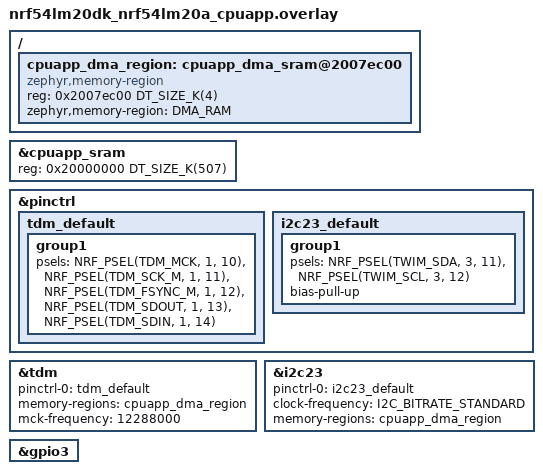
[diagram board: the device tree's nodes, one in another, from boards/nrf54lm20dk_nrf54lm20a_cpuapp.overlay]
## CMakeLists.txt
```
cmake_minimum_required(VERSION 3.20.0)
find_package(Zephyr REQUIRED HINTS $ENV{ZEPHYR_BASE})
project(flexlink_radio_test VERSION 0.1.0 LANGUAGES C)

set(TINYUSB_DIR ${CMAKE_CURRENT_SOURCE_DIR}/tinyusb)

if(DEFINED ZEPHYR_HAL_NORDIC_MODULE_DIR)
    set(HAL_NORDIC_DIR ${ZEPHYR_HAL_NORDIC_MODULE_DIR})
else()
    set(HAL_NORDIC_DIR ${ZEPHYR_BASE}/../modules/hal/nordic)
endif()

target_sources(app PRIVATE
    src/main.c
    src/app_control.c
    src/cli.c
    src/audio_io/audio_path_common.c
    src/audio_io/audio_path_wired.c
    src/audio_io/audio_path_wireless.c
    src/audio_io/i2s.c
    src/audio_io/i2s_tone.c
    src/audio_io/nau88l21.c
    src/prop_gfsk/radio_hw.c
    src/prop_gfsk/link.c
    src/prop_gfsk/test_mode.c
    src/usb/usb_device.c
    src/usb/usb_audio.c
    src/usb/usb_cdc.c
    src/usb/usb_descriptors.c
    ${TINYUSB_DIR}/src/tusb.c
    ${TINYUSB_DIR}/src/device/usbd.c
    ${TINYUSB_DIR}/src/device/usbd_control.c
    ${TINYUSB_DIR}/src/common/tusb_fifo.c
    ${TINYUSB_DIR}/src/class/cdc/cdc_device.c
    ${TINYUSB_DIR}/src/class/audio/audio_device.c
    ${TINYUSB_DIR}/src/portable/synopsys/dwc2/dcd_dwc2.c
    ${TINYUSB_DIR}/src/portable/synopsys/dwc2/dwc2_common.c
)

target_include_directories(app PRIVATE
    ${CMAKE_CURRENT_SOURCE_DIR}/src
    ${CMAKE_CURRENT_SOURCE_DIR}/src/usb
    ${ZEPHYR_BASE}/modules/hal_nordic/nrfx
    ${TINYUSB_DIR}/src
    ${TINYUSB_DIR}/hw
    ${TINYUSB_DIR}/hw/bsp
    ${TINYUSB_DIR}/hw/bsp/nrf
    ${TINYUSB_DIR}/hw/bsp/nrf/boards/nrf54lm20dk
    ${HAL_NORDIC_DIR}/nrfx
    ${HAL_NORDIC_DIR}/nrfx/lib
    ${HAL_NORDIC_DIR}/nrfx/mdk
    ${HAL_NORDIC_DIR}/nrfx/bsp/stable/mdk
    ${HAL_NORDIC_DIR}/nrfx/hal
    ${HAL_NORDIC_DIR}/nrfx/drivers/include
)

target_compile_definitions(app PRIVATE
    NRF54LM20A_ENGA_XXAA
)
```

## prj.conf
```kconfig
# Enable printk for console output
CONFIG_PRINTK=y

# Enable hwinfo for reading device unique ID
CONFIG_HWINFO=y

# Enable reboot API used by the CLI
CONFIG_REBOOT=y

# Deferred logging — non-blocking, flushes asynchronously
CONFIG_LOG=y
CONFIG_LOG_MODE_DEFERRED=y

# Enable basic audio serial and codec control drivers
CONFIG_I2S=y
CONFIG_I2S_NRF_TDM_TX_BLOCK_COUNT=16
CONFIG_I2S_NRF_TDM_RX_BLOCK_COUNT=16
CONFIG_I2C=y

# Enable k_poll() used by the pgfsk link thread
CONFIG_POLL=y

# Zephyr thread metadata for VS Code RTOS Views (Zephyr backend)
CONFIG_THREAD_MONITOR=y
CONFIG_THREAD_NAME=y
CONFIG_THREAD_STACK_INFO=y
CONFIG_INIT_STACKS=y

# Flash / RRAM driver
CONFIG_FLASH=y
CONFIG_SOC_FLASH_NRF_RRAM=y

# Settings / persistent profile storage
CONFIG_SETTINGS=y
CONFIG_SETTINGS_NVS=y
CONFIG_NVS=y
CONFIG_FLASH_MAP=y

# -O0, no inlining
# CONFIG_NO_OPTIMIZATIONS=y
```

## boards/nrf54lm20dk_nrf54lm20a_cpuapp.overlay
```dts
/*
 * Copyright (c) 2025 FlexAudioLink
 *
 * SPDX-License-Identifier: Apache-2.0
 */

#include <zephyr/dt-bindings/i2c/i2c.h>
#include <zephyr/dt-bindings/pinctrl/nrf-pinctrl.h>

/ {
	cpuapp_dma_region: cpuapp_dma_sram@2007ec00 {
		compatible = "zephyr,memory-region", "mmio-sram";
		reg = <0x2007ec00 DT_SIZE_K(4)>;
		#memory-region-cells = <0>;
		zephyr,memory-region = "DMA_RAM";
		status = "okay";
	};
};

&cpuapp_sram {
	/* Reserve 4 kB of DMA-safe RAM for TDM and TWIM EasyDMA buffers. */
	reg = <0x20000000 DT_SIZE_K(507)>;
	ranges = <0x0 0x20000000 0x7ec00>;
};

&pinctrl {
	tdm_default: tdm_default {
		group1 {
			psels = <NRF_PSEL(TDM_MCK, 1, 10)>,
				<NRF_PSEL(TDM_SCK_M, 1, 11)>,
				<NRF_PSEL(TDM_FSYNC_M, 1, 12)>,
				<NRF_PSEL(TDM_SDOUT, 1, 13)>,
				<NRF_PSEL(TDM_SDIN, 1, 14)>;
		};
	};

	i2c23_default: i2c23_default {
		group1 {
			psels = <NRF_PSEL(TWIM_SDA, 3, 11)>,
				<NRF_PSEL(TWIM_SCL, 3, 12)>;
			bias-pull-up;
		};
	};
};
&tdm {
	status = "okay";
	pinctrl-0 = <&tdm_default>;
	pinctrl-names = "default";
	memory-regions = <&cpuapp_dma_region>;
	mck-frequency = <12288000>;
};

&i2c23 {
	status = "okay";
	pinctrl-0 = <&i2c23_default>;
	pinctrl-names = "default";
	clock-frequency = <I2C_BITRATE_STANDARD>;
	memory-regions = <&cpuapp_dma_region>;
};

&gpio3 {
	status = "okay";
};
```

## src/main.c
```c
/*
 * FlexAudioLink nRF54 firmware
 *
 * Subsystems self-initialize via K_THREAD_DEFINE; main remains idle.
 */

int main(void)
{
	return 0;
}
```

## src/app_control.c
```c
#include "app_control.h"

#include "audio_io/audio_path_wired.h"
#include "audio_io/audio_path_wireless_dongle.h"
#include "audio_io/audio_path_wireless_headset.h"
#include "prop_gfsk/link.h"

#include <stdint.h>

#include <zephyr/kernel.h>
#include <zephyr/settings/settings.h>
#include <zephyr/sys/printk.h>

#define APP_PROFILE_SETTINGS_KEY "profile/active"

static enum app_profile g_current_profile = APP_PROFILE_USB;
static volatile bool g_boot_profile_ready;

enum app_profile app_control_get_current_profile(void)
{
	return g_current_profile;
}

bool app_control_boot_profile_ready(void)
{
	return g_boot_profile_ready;
}

const char *app_control_get_profile_name(enum app_profile profile)
{
	switch (profile) {
	case APP_PROFILE_USB:
		return "usb";
	case APP_PROFILE_PGFSK_DONGLE:
		return "pgfsk_dongle";
	case APP_PROFILE_PGFSK_HEADSET:
		return "pgfsk_headset";
	default:
		return "unknown";
	}
}

bool app_control_save_boot_profile(enum app_profile profile)
{
	if (profile >= APP_PROFILE_COUNT) {
		return false;
	}

	if (profile == g_current_profile) {
		return true;
	}

	uint8_t val = (uint8_t)profile;
	int rc = settings_save_one(APP_PROFILE_SETTINGS_KEY, &val, sizeof(val));
	if (rc) {
		printk("app_control: failed to persist profile (err %d)\n", rc);
		return false;
	}

	return true;
}

void app_control_boot(void)
{
	if (settings_subsys_init()) {
		printk("app_control: settings_subsys_init failed\n");
	}

	uint8_t saved;
	ssize_t rc = settings_load_one(APP_PROFILE_SETTINGS_KEY, &saved, sizeof(saved));
	if (rc == sizeof(saved) && saved < APP_PROFILE_COUNT) {
		g_current_profile = (enum app_profile)saved;
	} else {
		g_current_profile = APP_PROFILE_USB;
	}
	g_boot_profile_ready = true;

	printk("Boot profile: %s\n", app_control_get_profile_name(g_current_profile));

	switch (g_current_profile) {
	case APP_PROFILE_USB:
		audio_path_wired_init();
		break;
	case APP_PROFILE_PGFSK_DONGLE:
		if (!pgfsk_link_start_dongle()) {
			printk("app_control: failed to start pgfsk dongle link\n");
		}
		audio_path_wireless_dongle_init();
		break;
	case APP_PROFILE_PGFSK_HEADSET:
		if (!pgfsk_link_start_headset()) {
			printk("app_control: failed to start pgfsk headset link\n");
		}
		audio_path_wireless_headset_init();
		break;
	default:
		break;
	}
}
```

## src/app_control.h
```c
#pragma once

#include <stdbool.h>

enum app_profile {
	APP_PROFILE_USB,
	APP_PROFILE_PGFSK_DONGLE,
	APP_PROFILE_PGFSK_HEADSET,
	APP_PROFILE_COUNT,
};

void app_control_boot(void);
enum app_profile app_control_get_current_profile(void);
bool app_control_boot_profile_ready(void);
bool app_control_save_boot_profile(enum app_profile profile);
const char *app_control_get_profile_name(enum app_profile profile);
```

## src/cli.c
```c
#include "cli.h"

#include "app_control.h"
#include "audio_io/i2s.h"
#include "audio_io/audio_path_common.h"
#include "audio_io/audio_path_wired.h"
#include "audio_io/audio_path_wireless.h"
#include "audio_io/audio_path_wireless_dongle.h"
#include "audio_io/audio_path_wireless_headset.h"
#include "audio_io/nau88l21.h"
#include "prop_gfsk/link.h"
#include "prop_gfsk/test_mode.h"

#include <ctype.h>
#include <stdarg.h>
#include <stdbool.h>
#include <stdio.h>
#include <stdlib.h>
#include <string.h>
#include <strings.h>

#include <zephyr/kernel.h>
#include <zephyr/sys/reboot.h>

#include "tusb.h"

#define APP_FW_VERSION "0.1.0-nrf54" // TODO: auto-generate from git tag/commit
#define CLI_QUEUE_DEPTH 4
#define CLI_THREAD_STACK_SIZE 2048
#define CLI_THREAD_PRIORITY 10

static bool g_cli_connected;
static bool g_cli_echo_enabled = true;
static bool g_status_link_push_enabled;
static bool g_status_audio_push_enabled;
static uint32_t g_status_link_push_period_ms = 500;
static uint32_t g_status_audio_push_period_ms = 500;
static int64_t g_next_status_link_deadline_ms;
static int64_t g_next_status_audio_deadline_ms;
/* Complete command lines are queued here and executed by the low-priority CLI thread. */
K_MSGQ_DEFINE(g_cli_msgq, CLI_MAX_CMD_LEN, CLI_QUEUE_DEPTH, 4);
/* Async user-visible messages from other threads are serialized here. */
K_MSGQ_DEFINE(g_cli_output_msgq, CLI_MAX_OUTPUT_LEN, CLI_QUEUE_DEPTH, 4);

static void cli_process_line(char *line);
static void cli_thread(void *arg1, void *arg2, void *arg3);
static void cli_init(void);
static void cli_print(const char *fmt, ...);

static size_t cli_strnlen(const char *s, size_t max_len)
{
	size_t len = 0U;

	if (s == NULL) {
		return 0U;
	}

	while (len < max_len && s[len] != '\0') {
		len++;
	}

	return len;
}

static void cli_write_raw(const char *data, size_t len)
{
	uint32_t written = 0U;

	if (!g_cli_connected || !tud_cdc_connected() || data == NULL || len == 0U) {
		return;
	}

	while (written < len) {
		uint32_t pushed = tud_cdc_write(data + written, len - written);

		if (pushed == 0U) {
			break;
		}

		written += pushed;
	}

	tud_cdc_write_flush();
}

static void cli_print(const char *fmt, ...)
{
	char buf[CLI_MAX_OUTPUT_LEN];
	va_list args;
	int len;

	va_start(args, fmt);
	len = vsnprintf(buf, sizeof(buf), fmt, args);
	va_end(args);

	if (len <= 0) {
		return;
	}

	if (len > (int)(sizeof(buf) - 1)) {
		len = sizeof(buf) - 1;
	}

	cli_write_raw(buf, (size_t)len);
}

static void cli_emit_status_link_push(void)
{
	struct pgfsk_link_report stats;
	uint32_t loss_permille = 0U;

	pgfsk_link_get_report(&stats);

	if ((stats.rx_ok_count + stats.packets_lost_in_service) > 0U) {
		loss_permille = (stats.packets_lost_in_service * 1000U) /
			(stats.rx_ok_count + stats.packets_lost_in_service);
	}

	cli_print("#L rssi=%d loss=%u.%u tx=%u rx_ok=%u "
		  "lost=%u crc_err=%u dlate=%u rx_incmplt=%u txf=%u "
		  "lb1=%u lb2=%u lb34=%u lb5p=%u lbmax=%u "
		  "outages=%u in_service_ms=%llu\n",
		  stats.last_rssi_dbm,
		  loss_permille / 10U,
		  loss_permille % 10U,
		  stats.packets_tx,
		  stats.rx_ok_count,
		  stats.packets_lost_in_service,
		  stats.crc_error_count,
		  stats.deadline_late_count,
		  stats.rx_incomplete_count,
		  stats.tx_trigger_fail_count,
		  stats.loss_burst_1_count,
		  stats.loss_burst_2_count,
		  stats.loss_burst_3_4_count,
		  stats.loss_burst_5_plus_count,
		  stats.max_loss_burst_len,
		  stats.outage_count,
		  stats.time_in_service_us / 1000U);
}

static void cli_emit_status_audio_push(void)
{
	enum app_profile profile = app_control_get_current_profile();

	switch (profile) {
	case APP_PROFILE_USB: {
		struct audio_path_wired_status s;

		audio_path_wired_get_status(&s);
		cli_print("#A state=%s spk_level_bytes=%u "
			  "spk_fifo_bytes=%u spk_pending_bytes=%u "
			  "spk_filtered_level_bytes=%u spk_error_bytes=%d spk_p_adjust_hz=%d "
			  "spk_fll_target_rate_hz=%d spk_fll_fails=%u spk_underruns=%u "
			  "mic_level_bytes=%u mic_overruns=%u\n",
			  audio_path_get_state_name(s.stream_state),
			  s.spk_level_bytes,
			  s.spk_fifo_bytes,
			  s.spk_pending_bytes,
			  s.spk_filtered_level_bytes,
			  s.spk_error_bytes,
			  s.spk_p_adjust_hz,
			  s.spk_fll_target_rate_hz,
			  s.spk_fll_fails,
			  s.spk_underrun_events,
			  s.mic_level_bytes,
			  s.mic_overflow_bytes);
		return;
	}
	case APP_PROFILE_PGFSK_DONGLE: {
		struct audio_path_wireless_status s;

		audio_path_wireless_dongle_get_status(&s);
		cli_print("#A state=%s spk_level_bytes=%u "
			  "spk_underruns=%u overruns=%u spk_silence_bytes=%u "
			  "spk_dropped_oldest_bytes=%u spk_usb_level_bytes=%u mic_usb_level_bytes=%u\n",
			  audio_path_get_state_name(s.stream_state),
			  s.spk_level_bytes,
			  s.spk_underrun_bytes,
			  s.overflow_bytes,
			  s.spk_silence_inserted_bytes,
			  s.spk_dropped_oldest_bytes,
			  s.spk_usb_level_bytes,
			  s.mic_usb_level_bytes);
		return;
	}
	case APP_PROFILE_PGFSK_HEADSET: {
		struct audio_path_wireless_status s;

		audio_path_wireless_headset_get_status(&s);
		cli_print("#A state=%s spk_level_bytes=%u "
			  "spk_filtered_level_bytes=%u spk_p_adjust_hz=%d "
			  "spk_fll_target_rate_hz=%d spk_fll_fails=%u "
			  "spk_underruns=%u overruns=%u spk_silence_bytes=%u "
			  "spk_dropped_oldest_bytes=%u\n",
			  audio_path_get_state_name(s.stream_state),
			  s.spk_level_bytes,
			  s.spk_filtered_level_bytes,
			  s.spk_p_adjust_hz,
			  s.spk_fll_target_rate_hz,
			  s.spk_fll_fails,
			  s.spk_underrun_bytes,
			  s.overflow_bytes,
			  s.spk_silence_inserted_bytes,
			  s.spk_dropped_oldest_bytes);
		return;
	}
	default:
		cli_print("#A state=none\n");
		return;
	}
}

static uint32_t cli_parse_status_period_ms(char *args_after_on)
{
	unsigned long value = 500UL;

	while (args_after_on != NULL && (*args_after_on == ' ' || *args_after_on == '\t')) {
		++args_after_on;
	}

	if (args_after_on != NULL && *args_after_on != '\0') {
		value = strtoul(args_after_on, NULL, 10);
		if (value == 0UL) {
			value = 500UL;
		}
	}

	return (uint32_t)value;
}

static void cli_print_profile_group(void)
{
	cli_print("[profile]\n");
	cli_print("profile=%s\n", app_control_get_profile_name(app_control_get_current_profile()));
}

static void cli_print_radio_group(void)
{
	cli_print("[radio]\n");
	cli_print("phy_rate=4\n");
	cli_print("tx_power=8\n");
	cli_print("fhss_exclusion=none\n");
	cli_print("payload_ms_dl=1\n");
	cli_print("payload_ms_ul=1\n");
	cli_print("jitter_buffer_ms=10\n");
}

static void cli_print_device_group(void)
{
	const char *audio_io;

	switch (app_control_get_current_profile()) {
	case APP_PROFILE_USB:
		audio_io = "wired";
		break;
	case APP_PROFILE_PGFSK_DONGLE:
		audio_io = "usb";
		break;
	case APP_PROFILE_PGFSK_HEADSET:
		audio_io = "codec";
		break;
	default:
		audio_io = "unknown";
		break;
	}

	cli_print("[device]\n");
	cli_print("audio_io=%s\n", audio_io);
	cli_print("device_addr=0xD0D0D0D0\n");
	cli_print("peer_addr=0xA1A1A1A1\n");
	cli_print("auto_sleep=0\n");
	cli_print("low_battery_threshold=10\n");
}

static void cli_print_audio_group(void)
{
	cli_print("[audio]\n");
	cli_print("sample_rate_spk=48000\n");
	cli_print("bit_width_spk=16\n");
	cli_print("channels_spk=stereo\n");
	cli_print("codec_spk=pcm\n");
	cli_print("volume=80\n");
	cli_print("sidetone=0\n");
	cli_print("sample_rate_mic=48000\n");
	cli_print("bit_width_mic=16\n");
	cli_print("channels_mic=mono\n");
	cli_print("codec_mic=pcm\n");
	cli_print("mic_gain=12\n");
	cli_print("mic_mute=off\n");
}

static void cli_print_eq_group(void)
{
	cli_print("[eq]\n");
	cli_print("eq0=100,0\n");
	cli_print("eq1=400,0\n");
	cli_print("eq2=1000,0\n");
	cli_print("eq3=4000,0\n");
	cli_print("eq4=10000,0\n");
}

static void cli_print_help(void)
{
	cli_print("Available commands:\n");
	cli_print("  help\n");
	cli_print("  echo on|off\n");
	cli_print("  get <group|param>\n");
	cli_print("  set profile <usb|pgfsk_dongle|pgfsk_headset>\n");
	cli_print("  i2s tone on|off|status\n");
	cli_print("  linktest on|off|status\n");
	cli_print("  status_link on [ms]|off\n");
	cli_print("  status_audio on [ms]|off\n");
	cli_print("  fll auto|status|<rate_hz>\n");
	cli_print("  reset\n");
	cli_print("  scan\n");
}

static void cli_cmd_get(const char *arg)
{
	if (arg == NULL || *arg == '\0' || strcasecmp(arg, "all") == 0) {
		cli_print_audio_group();
		cli_print_radio_group();
		cli_print_profile_group();
		cli_print_device_group();
		cli_print_eq_group();
		return;
	}

	if (strcasecmp(arg, "profile") == 0) {
		cli_print_profile_group();
		return;
	}

	if (strcasecmp(arg, "radio") == 0) {
		cli_print_radio_group();
		return;
	}

	if (strcasecmp(arg, "device") == 0) {
		cli_print_device_group();
		return;
	}

	if (strcasecmp(arg, "audio") == 0) {
		cli_print_audio_group();
		return;
	}

	if (strcasecmp(arg, "eq") == 0) {
		cli_print_eq_group();
		return;
	}

	cli_print("ERR %s unknown_param\n", arg);
}

static void cli_cmd_set(char *args)
{
	char *param = strtok(args, " \t");
	char *value = strtok(NULL, "");

	if (param == NULL || value == NULL) {
		cli_print("ERR set invalid_args\n");
		return;
	}

	while (*value == ' ' || *value == '\t') {
		++value;
	}

	if (strcasecmp(param, "profile") == 0) {
		enum app_profile profile;

		if (strcasecmp(value, "usb") == 0) {
			profile = APP_PROFILE_USB;
		} else if (strcasecmp(value, "pgfsk_dongle") == 0) {
			profile = APP_PROFILE_PGFSK_DONGLE;
		} else if (strcasecmp(value, "pgfsk_headset") == 0) {
			profile = APP_PROFILE_PGFSK_HEADSET;
		} else {
			cli_print("ERR profile invalid_value\n");
			return;
		}

		if (profile == app_control_get_current_profile()) {
			cli_print("OK profile=%s\n", app_control_get_profile_name(profile));
			return;
		}

		if (!app_control_save_boot_profile(profile)) {
			cli_print("ERR profile persist_failed\n");
			return;
		}

		cli_print("OK profile=%s\nrebooting...\n", app_control_get_profile_name(profile));
		tud_cdc_write_flush();
		k_sleep(K_MSEC(50));
		sys_reboot(SYS_REBOOT_COLD);
		/* sys_reboot does not return; surface error if it does. */
		cli_print("ERR profile reboot_failed\n");
		return;
	}

	cli_print("ERR %s unsupported\n", param);
}

static void cli_cmd_linktest(char *args)
{
	if (args == NULL || *args == '\0' || strcasecmp(args, "status") == 0) {
		cli_print("linktest=%s\n", pgfsk_test_mode_is_running() ? "on" : "off");
		return;
	}

	if (strcasecmp(args, "on") == 0) {
		if (!pgfsk_test_mode_start()) {
			cli_print("ERR linktest start_failed\n");
			return;
		}

		cli_print("OK linktest=on\n");
		return;
	}

	if (strcasecmp(args, "off") == 0) {
		if (!pgfsk_test_mode_stop()) {
			cli_print("ERR linktest stop_failed\n");
			return;
		}

		cli_print("OK linktest=off\n");
		return;
	}

	cli_print("ERR linktest invalid_value\n");
}

static void cli_cmd_status_link(char *args)
{
	if (args == NULL || *args == '\0') {
		cli_print("ERR status_link invalid_value\n");
		return;
	}

	if (strncasecmp(args, "on", 2) == 0) {
		g_status_link_push_period_ms = cli_parse_status_period_ms(args + 2);
		g_status_link_push_enabled = true;
		g_next_status_link_deadline_ms = k_uptime_get() + g_status_link_push_period_ms;
		cli_print("OK status_link=%u\n", g_status_link_push_period_ms);
		return;
	}

	if (strcasecmp(args, "off") == 0) {
		g_status_link_push_enabled = false;
		cli_print("OK status_link=off\n");
		return;
	}

	cli_print("ERR status_link invalid_value\n");
}

static void cli_cmd_status_audio(char *args)
{
	if (args == NULL || *args == '\0') {
		cli_print("ERR status_audio invalid_value\n");
		return;
	}

	if (strncasecmp(args, "on", 2) == 0) {
		g_status_audio_push_period_ms = cli_parse_status_period_ms(args + 2);
		g_status_audio_push_enabled = true;
		g_next_status_audio_deadline_ms = k_uptime_get() + g_status_audio_push_period_ms;
		cli_print("OK status_audio=%u\n", g_status_audio_push_period_ms);
		return;
	}

	if (strcasecmp(args, "off") == 0) {
		g_status_audio_push_enabled = false;
		cli_print("OK status_audio=off\n");
		return;
	}

	cli_print("ERR status_audio invalid_value\n");
}

static void cli_cmd_fll(char *args)
{
	long rate;
	int32_t lo, hi;
	enum app_profile profile = app_control_get_current_profile();

	if (args == NULL || *args == '\0' || strcasecmp(args, "auto") == 0) {
		switch (profile) {
		case APP_PROFILE_USB:
			audio_path_wired_fll_set_auto();
			break;
		case APP_PROFILE_PGFSK_HEADSET:
			audio_path_wireless_headset_fll_set_auto();
			break;
		default:
			cli_print("ERR fll not available for current profile\n");
			return;
		}
		cli_print("OK fll=auto (P-controller running)\n");
		return;
	}

	if (strcasecmp(args, "status") == 0) {
		int32_t fixed = (profile == APP_PROFILE_PGFSK_HEADSET)
			? audio_path_wireless_headset_fll_get_fixed_rate()
			: audio_path_wired_fll_get_fixed_rate();

		if (fixed != 0) {
			cli_print("OK fll=fixed target_rate=%d\n", fixed);
		} else {
			cli_print("OK fll=auto\n");
		}
		return;
	}

	if (profile == APP_PROFILE_PGFSK_DONGLE) {
		cli_print("ERR fll not available for dongle profile\n");
		return;
	}

	lo = (int32_t)(AUDIO_I2S_SAMPLE_RATE_HZ - AUDIO_P_ADJUST_MAX_HZ);
	hi = (int32_t)(AUDIO_I2S_SAMPLE_RATE_HZ + AUDIO_P_ADJUST_MAX_HZ);

	rate = strtol(args, NULL, 10);
	if (rate < lo || rate > hi) {
		cli_print("ERR fll rate %ld out of range (%d-%d)\n", rate, lo, hi);
		return;
	}

	if (profile == APP_PROFILE_PGFSK_HEADSET) {
		audio_path_wireless_headset_fll_set_fixed((int32_t)rate);
		if (audio_path_wireless_headset_fll_get_fixed_rate() == 0) {
			cli_print("ERR fll driver rejected rate %ld\n", rate);
		} else {
			cli_print("OK fll=fixed target_rate=%ld (P-controller paused)\n", rate);
		}
	} else {
		audio_path_wired_fll_set_fixed((int32_t)rate);
		if (audio_path_wired_fll_get_fixed_rate() == 0) {
			cli_print("ERR fll driver rejected rate %ld\n", rate);
		} else {
			cli_print("OK fll=fixed target_rate=%ld (P-controller paused)\n", rate);
		}
	}
}

static void cli_process_line(char *line)
{
	char *cmd;
	char *args;

	if (line == NULL) {
		return;
	}

	while (isspace((unsigned char)*line)) {
		++line;
	}

	if (*line == '\0') {
		return;
	}

	cmd = strtok(line, " \t");
	args = strtok(NULL, "");

	if (g_cli_echo_enabled) {
		cli_print("%s%s%s\n", cmd, args ? " " : "", args ? args : "");
	}

	if (strcasecmp(cmd, "help") == 0) {
		cli_print_help();
		return;
	}

	if (strcasecmp(cmd, "echo") == 0) {
		if (args == NULL || strcasecmp(args, "on") == 0) {
			g_cli_echo_enabled = true;
			cli_print("OK echo=on\n");
		} else if (strcasecmp(args, "off") == 0) {
			g_cli_echo_enabled = false;
			cli_print("OK echo=off\n");
		} else {
			cli_print("ERR echo invalid_value\n");
		}
		return;
	}

	if (strcasecmp(cmd, "status_link") == 0) {
		cli_cmd_status_link(args);
		return;
	}

	if (strcasecmp(cmd, "status_audio") == 0) {
		cli_cmd_status_audio(args);
		return;
	}

	if (strcasecmp(cmd, "get") == 0) {
		cli_cmd_get(args);
		return;
	}

	if (strcasecmp(cmd, "set") == 0) {
		cli_cmd_set(args);
		return;
	}

	if (strcasecmp(cmd, "linktest") == 0) {
		cli_cmd_linktest(args);
		return;
	}

	if (strcasecmp(cmd, "scan") == 0) {
		cli_print("ERR %s unsupported\n", cmd);
		return;
	}

	if (strcasecmp(cmd, "reset") == 0) {
		cli_print("OK reset\n");
		sys_reboot(SYS_REBOOT_COLD);
		return;
	}

	if (strcasecmp(cmd, "fll") == 0) {
		cli_cmd_fll(args);
		return;
	}

	cli_print("ERR %s unknown_command\n", cmd);
}

static void cli_init(void)
{
	g_cli_echo_enabled = true;
	g_status_link_push_enabled = false;
	g_status_audio_push_enabled = false;
	g_status_link_push_period_ms = 500;
	g_status_audio_push_period_ms = 500;
	g_next_status_link_deadline_ms = 0;
	g_next_status_audio_deadline_ms = 0;
	k_msgq_purge(&g_cli_msgq);
	k_msgq_purge(&g_cli_output_msgq);
}

void cli_set_connected(bool connected)
{
	bool announce = connected && !g_cli_connected;

	g_cli_connected = connected;

	if (announce) {
		static const char welcome[] = "FlexAudioLink CLI\nType 'help' for commands\n";

		cli_write_raw(welcome, sizeof(welcome) - 1U);
	}
}

void cli_enqueue_command_line(char *line)
{
	char queued_line[CLI_MAX_CMD_LEN];
	size_t len;

	if (line == NULL) {
		return;
	}

	len = cli_strnlen(line, CLI_MAX_CMD_LEN - 1U);
	memcpy(queued_line, line, len);
	queued_line[len] = '\0';
	/* Drop on overflow rather than blocking the USB path. */
	(void)k_msgq_put(&g_cli_msgq, queued_line, K_NO_WAIT);
}

void cli_enqueue_print_msg(const char *message)
{
	char queued_message[CLI_MAX_OUTPUT_LEN];
	size_t len;

	if (message == NULL) {
		return;
	}

	len = cli_strnlen(message, CLI_MAX_OUTPUT_LEN - 1U);
	memcpy(queued_message, message, len);
	queued_message[len] = '\0';
	(void)k_msgq_put(&g_cli_output_msgq, queued_message, K_NO_WAIT);
}

static void cli_thread(void *arg1, void *arg2, void *arg3)
{
	char line[CLI_MAX_CMD_LEN];
	char message[CLI_MAX_OUTPUT_LEN];

	ARG_UNUSED(arg1);
	ARG_UNUSED(arg2);
	ARG_UNUSED(arg3);

	/* The CLI thread owns CLI-core initialization. Transport hookup stays
	 * outside so USB can attach/detach independently.
	 */
	cli_init();

	/* Mirrors the old FreeRTOS design: USB input is decoupled from command execution. */
	while (1) {
		if (k_msgq_get(&g_cli_msgq, line, K_MSEC(10)) == 0) {
			cli_process_line(line);
		}

		if (k_msgq_get(&g_cli_output_msgq, message, K_NO_WAIT) == 0) {
			cli_write_raw(message, strlen(message));
		}

		if (g_status_link_push_enabled && g_cli_connected && k_uptime_get() >= g_next_status_link_deadline_ms) {
			cli_emit_status_link_push();
			g_next_status_link_deadline_ms = k_uptime_get() + g_status_link_push_period_ms;
		}

		if (g_status_audio_push_enabled && g_cli_connected && k_uptime_get() >= g_next_status_audio_deadline_ms) {
			cli_emit_status_audio_push();
			g_next_status_audio_deadline_ms = k_uptime_get() + g_status_audio_push_period_ms;
		}
	}
}

K_THREAD_DEFINE(cli_thread_id, CLI_THREAD_STACK_SIZE, cli_thread, NULL, NULL, NULL, CLI_THREAD_PRIORITY, 0, 0);
```

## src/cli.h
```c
#pragma once

#include <stddef.h>
#include <stdbool.h>

#define CLI_MAX_CMD_LEN 128
#define CLI_MAX_OUTPUT_LEN 192

void cli_set_connected(bool connected);
void cli_enqueue_command_line(char *line);
void cli_enqueue_print_msg(const char *message);
```

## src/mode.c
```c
#include "mode.h"

#include "cli.h"
#include "proprietary/link.h"
#include "proprietary/radio_hw.h"
#include "proprietary/test_mode.h"
#include "usb/usb_device.h"

#include <string.h>

#include <zephyr/drivers/hwinfo.h>
#include <zephyr/kernel.h>
#include <zephyr/sys/printk.h>

#define MODE_THREAD_STACK_SIZE 2048
#define MODE_THREAD_PRIORITY 9
#define MODE_MSGQ_DEPTH 4

#define MODE_DEFAULT_ROLE DEVICE_ROLE_HEADSET

static struct app_mode_state mode_current_state = {
	.role = DEVICE_ROLE_HEADSET,
	.mode = OPERATING_MODE_PROPRIETARY,
};
K_MSGQ_DEFINE(g_mode_msgq, sizeof(struct app_mode_state), MODE_MSGQ_DEPTH, 4);

static void mode_apply_state(struct app_mode_state state)
{
	enum usb_device_profile usb_profile =
		(state.mode == OPERATING_MODE_USB) ?
			USB_DEVICE_PROFILE_UAC_CDC :
			USB_DEVICE_PROFILE_CDC;
	bool proprietary_test_mode_enabled =
		(state.mode == OPERATING_MODE_PROPRIETARY);

	usb_device_request_profile(usb_profile);
	proprietary_test_mode_set_enabled(proprietary_test_mode_enabled,
					  state.role);
}

static void mode_announce_applied_state(struct app_mode_state state)
{
	char message[CLI_MAX_OUTPUT_LEN];
	int len;

	len = snprintf(message, sizeof(message),
		       "OK applied role=%s mode=%s\n",
		       mode_get_role_name(state.role),
		       mode_get_operating_mode_name(state.mode));
	if (len <= 0) {
		return;
	}

	cli_enqueue_print_msg(message);
}

static struct app_mode_state mode_get_latest_state(void)
{
	struct app_mode_state state = mode_current_state;

	(void)k_msgq_peek(&g_mode_msgq, &state);
	return state;
}

static bool mode_state_is_valid(struct app_mode_state state)
{
	if (state.role != DEVICE_ROLE_DONGLE &&
	    state.role != DEVICE_ROLE_HEADSET) {
		return false;
	}

	if (state.mode != OPERATING_MODE_PROPRIETARY &&
	    state.mode != OPERATING_MODE_BLE &&
	    state.mode != OPERATING_MODE_USB) {
		return false;
	}

	if (state.role == DEVICE_ROLE_DONGLE &&
	    state.mode == OPERATING_MODE_USB) {
		return false;
	}

	return true;
}

static void mode_enqueue_state(struct app_mode_state state)
{
	k_msgq_purge(&g_mode_msgq);
	(void)k_msgq_put(&g_mode_msgq, &state, K_NO_WAIT);
}

static bool mode_request_state(struct app_mode_state state)
{
	if (!mode_state_is_valid(state)) {
		return false;
	}

	mode_enqueue_state(state);
	return true;
}

static enum device_role mode_detect_default_role(void)
{
	uint8_t id[16];
	ssize_t len;
	uint64_t uid = 0;
	int copy_len;

	len = hwinfo_get_device_id(id, sizeof(id));
	if (len < 0) {
		printk("hwinfo_get_device_id failed: %zd\n", len);
		return MODE_DEFAULT_ROLE;
	}

	printk("Device UID (%zd bytes):", len);
	for (int i = 0; i < len; i++) {
		printk(" %02x", id[i]);
	}
	printk("\n");

	copy_len = (len < 8) ? len : 8;
	memcpy(&uid, id, copy_len);
	printk("Device UID (u64): 0x%016llx\n", uid);

	if (TX_DEVICE_ID != 0 && uid == TX_DEVICE_ID) {
		return DEVICE_ROLE_DONGLE;
	}

	return MODE_DEFAULT_ROLE;
}

static void mode_thread(void *arg1, void *arg2, void *arg3)
{
	struct app_mode_state requested_state;

	ARG_UNUSED(arg1);
	ARG_UNUSED(arg2);
	ARG_UNUSED(arg3);

	proprietary_link_init();
	proprietary_test_mode_init();

	mode_current_state = (struct app_mode_state){
		.role = mode_detect_default_role(),
		.mode = OPERATING_MODE_PROPRIETARY,
	};
	mode_apply_state(mode_current_state);

	printk("Default role: %s\n", mode_get_role_name(mode_current_state.role));
	printk("Default mode: %s\n",
	       mode_get_operating_mode_name(mode_current_state.mode));

	while (1) {
		if (k_msgq_get(&g_mode_msgq, &requested_state, K_FOREVER) != 0) {
			continue;
		}

		if (requested_state.role == mode_current_state.role &&
		    requested_state.mode == mode_current_state.mode) {
			continue;
		}

		mode_apply_state(requested_state);
		mode_current_state = requested_state;
		mode_announce_applied_state(mode_current_state);
	}
}

struct app_mode_state mode_get_current_state(void)
{
	return mode_current_state;
}

enum device_role mode_get_current_role(void)
{
	return mode_get_current_state().role;
}

enum operating_mode mode_get_current_operating_mode(void)
{
	return mode_get_current_state().mode;
}

bool mode_request_role(enum device_role role)
{
	struct app_mode_state state;

	state = mode_get_latest_state();

	if (state.role == role) {
		return true;
	}

	state.role = role;

	if (state.role == DEVICE_ROLE_DONGLE &&
	    state.mode == OPERATING_MODE_USB) {
		state.mode = OPERATING_MODE_PROPRIETARY;
	}

	return mode_request_state(state);
}

bool mode_request_operating_mode(enum operating_mode mode)
{
	struct app_mode_state state;

	state = mode_get_latest_state();

	if (state.mode == mode) {
		return true;
	}

	state.mode = mode;
	return mode_request_state(state);
}

const char *mode_get_role_name(enum device_role role)
{
	switch (role) {
	case DEVICE_ROLE_DONGLE:
		return "dongle";
	case DEVICE_ROLE_HEADSET:
		return "headset";
	default:
		return "unknown";
	}
}

const char *mode_get_operating_mode_name(enum operating_mode mode)
{
	switch (mode) {
	case OPERATING_MODE_PROPRIETARY:
		return "proprietary";
	case OPERATING_MODE_BLE:
		return "ble";
	case OPERATING_MODE_USB:
		return "usb";
	default:
		return "unknown";
	}
}

K_THREAD_DEFINE(mode_thread_id, MODE_THREAD_STACK_SIZE, mode_thread,
		NULL, NULL, NULL, MODE_THREAD_PRIORITY, 0, 0);
```

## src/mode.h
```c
#pragma once

#include <stdbool.h>
#include <stdint.h>

enum device_role {
	DEVICE_ROLE_DONGLE,
	DEVICE_ROLE_HEADSET,
};

enum operating_mode {
	OPERATING_MODE_PROPRIETARY,
	OPERATING_MODE_BLE,
	OPERATING_MODE_USB,
};

struct app_mode_state {
	enum device_role role;
	enum operating_mode mode;
};

struct app_mode_state mode_get_current_state(void);
enum device_role mode_get_current_role(void);
enum operating_mode mode_get_current_operating_mode(void);
bool mode_request_role(enum device_role role);
bool mode_request_operating_mode(enum operating_mode mode);
const char *mode_get_role_name(enum device_role role);
const char *mode_get_operating_mode_name(enum operating_mode mode);
```

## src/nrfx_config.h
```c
#pragma once

#include "../tinyusb/hw/bsp/nrf/nrfx_config/nrfx_config.h"
```

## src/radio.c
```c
#include "radio.h"
#include <hal/nrf_clock.h>
#include <soc.h>

/***************************************************************************
 * Shared state
 ***************************************************************************/

struct radio_packet pkt_tx;
struct radio_packet pkt_rx[2];
volatile uint8_t rx_buf_idx;
bool is_tx;

K_SEM_DEFINE(tx_done_sem, 1, 1);
K_SEM_DEFINE(rx_sem, 0, 1);
volatile int16_t rx_rssi;
volatile uint8_t rx_ready_idx;

/***************************************************************************
 * HFCLK startup
 ***************************************************************************/

static void hfclk_start(void)
{
    nrf_clock_event_clear(NRF_CLOCK, NRF_CLOCK_EVENT_HFCLKSTARTED);
    nrf_clock_task_trigger(NRF_CLOCK, NRF_CLOCK_TASK_HFCLKSTART);
    while (!nrf_clock_event_check(NRF_CLOCK, NRF_CLOCK_EVENT_HFCLKSTARTED)) {
        /* spin */
    }
}

/***************************************************************************
 * Radio ISR - dispatches based on runtime role
 ***************************************************************************/

static void radio_isr(const void *arg)
{
    (void)arg;

    if (is_tx) {
        if (nrf_radio_event_check(NRF_RADIO, NRF_RADIO_EVENT_DISABLED)) {
            nrf_radio_event_clear(NRF_RADIO, NRF_RADIO_EVENT_DISABLED);
            k_sem_give(&tx_done_sem);
        }
    } else {
        if (nrf_radio_event_check(NRF_RADIO, NRF_RADIO_EVENT_CRCERROR)) {
            nrf_radio_event_clear(NRF_RADIO, NRF_RADIO_EVENT_CRCERROR);
            nrf_radio_task_trigger(NRF_RADIO, NRF_RADIO_TASK_START);
            return;
        }

        if (nrf_radio_event_check(NRF_RADIO, NRF_RADIO_EVENT_PHYEND)) {
            nrf_radio_event_clear(NRF_RADIO, NRF_RADIO_EVENT_PHYEND);

            rx_rssi = nrf_radio_rssi_sample_get(NRF_RADIO);

            rx_ready_idx = rx_buf_idx;
            rx_buf_idx ^= 1;
            nrf_radio_packetptr_set(NRF_RADIO, (uint32_t *)&pkt_rx[rx_buf_idx]);

            nrf_radio_task_trigger(NRF_RADIO, NRF_RADIO_TASK_START);

            k_sem_give(&rx_sem);
        }
    }
}

/***************************************************************************
 * Radio initialization
 ***************************************************************************/

void radio_init(void)
{
    hfclk_start();

    nrf_radio_mode_set(NRF_RADIO, MODE);
    nrf_radio_frequency_set(NRF_RADIO, FREQ);
    nrf_radio_txpower_set(NRF_RADIO, TXPOWER);

    nrf_radio_packet_conf_t pkt_conf = {
        .lflen = 0,
        .s0len = 0,
        .s1len = 0,
        .s1incl = false,
        .plen = NRF_RADIO_PREAMBLE_LENGTH_8BIT,
        .crcinc = false,
        .maxlen = sizeof(struct radio_packet),
        .statlen = sizeof(struct radio_packet),
        .balen = 3,
        .big_endian = false,
        .whiteen = true,
    };
    nrf_radio_packet_configure(NRF_RADIO, &pkt_conf);

    nrf_radio_datawhiteiv_set(NRF_RADIO, (FREQ - 2400) & 0x3F);

    nrf_radio_crc_configure(NRF_RADIO,
        2,
        NRF_RADIO_CRC_ADDR_SKIP,
        0x11021UL);

    nrf_radio_base0_set(NRF_RADIO, SYNC_WORD);
    nrf_radio_txaddress_set(NRF_RADIO, 0);
    nrf_radio_rxaddresses_set(NRF_RADIO, 1 << 0);

    IRQ_CONNECT(RADIO_0_IRQn, 0, radio_isr, NULL, 0);
}
```

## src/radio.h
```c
#ifndef RADIO_H
#define RADIO_H

#include <zephyr/kernel.h>
#include <hal/nrf_radio.h>

/***************************************************************************
 * Configuration
 ***************************************************************************/

#define SYNC_WORD           0xD391A5D3UL

#define FREQ                2480        /* Absolute frequency in MHz */
#define TXPOWER             NRF_RADIO_TXPOWER_POS8DBM
#define MODE                NRF_RADIO_MODE_NRF_4MBIT_BT_0_6

#define INTERVAL_MS         1           /* 1 ms between packets */

#define PAYLOAD_LEN         250
#define PACKET_LEN          (2 + PAYLOAD_LEN)

#define TX_DEVICE_ID        0xb007ec2fe3f4e0c0ULL

/***************************************************************************
 * Packet structure
 ***************************************************************************/

struct radio_packet {
    uint16_t seq;
    uint8_t  data[PAYLOAD_LEN];
} __packed __aligned(4);

/***************************************************************************
 * Shared state (defined in radio.c)
 ***************************************************************************/

extern struct radio_packet pkt_tx;
extern struct radio_packet pkt_rx[2];
extern volatile uint8_t rx_buf_idx;
extern bool is_tx;

extern struct k_sem tx_done_sem;
extern struct k_sem rx_sem;
extern volatile int16_t rx_rssi;
extern volatile uint8_t rx_ready_idx;

/***************************************************************************
 * Functions
 ***************************************************************************/

void radio_init(void);
void run_tx(void);
void run_rx(void);

#endif /* RADIO_H */
```

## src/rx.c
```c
#include "radio.h"
#include <zephyr/sys/printk.h>
#include <zephyr/logging/log.h>
#include <stdlib.h>

LOG_MODULE_REGISTER(radio_test, LOG_LEVEL_INF);

void run_rx(void)
{
    printk("\n=== FlexLink Radio Test RX ===\n");
    printk("Frequency: %u MHz\n", FREQ);
    printk("Rate: 4 Mbps\n");
    printk("Payload: %u bytes\n", PAYLOAD_LEN);
    printk("Sync word: 0x%08lX\n\n", SYNC_WORD);

    rx_buf_idx = 0;
    nrf_radio_packetptr_set(NRF_RADIO, (uint32_t *)&pkt_rx[0]);

    nrf_radio_shorts_enable(NRF_RADIO,
        NRF_RADIO_SHORT_READY_START_MASK |
        NRF_RADIO_SHORT_ADDRESS_RSSISTART_MASK);

    nrf_radio_int_enable(NRF_RADIO,
        NRF_RADIO_INT_CRCERROR_MASK |
        NRF_RADIO_INT_PHYEND_MASK);

    nrf_radio_event_clear(NRF_RADIO, NRF_RADIO_EVENT_CRCERROR);
    nrf_radio_event_clear(NRF_RADIO, NRF_RADIO_EVENT_PHYEND);
    nrf_radio_event_clear(NRF_RADIO, NRF_RADIO_EVENT_READY);

    irq_enable(RADIO_0_IRQn);

    nrf_radio_task_trigger(NRF_RADIO, NRF_RADIO_TASK_RXEN);

    uint16_t last_seq = 0;
    uint32_t total = 0;
    uint32_t lost = 0;
    int64_t rssi_sum = 0;
    int64_t last_time = 0;
    int64_t last_print = 0;
    uint32_t expected_interval_us = INTERVAL_MS * 1000;
    uint16_t consec_drop = 0;
    uint16_t max_burst_drop = 0;
    /* IAT deviation stats (in us) */
    int64_t iat_min = INT64_MAX;
    int64_t iat_max = 0;
    int64_t iat_sum = 0;
    uint32_t iat_count = 0;
    uint32_t iat_hist[6] = { 0 };

    while (1) {
        if (k_sem_take(&rx_sem, K_MSEC(100)) == 0) {
            uint8_t idx = rx_ready_idx;
            uint16_t seq = pkt_rx[idx].seq;
            int16_t rssi = rx_rssi;

            uint16_t expected = last_seq + 1;
            if (seq != expected && last_seq != 0) {
                uint16_t gap = (uint16_t)(seq - expected);
                /* Ignore seq wraparound */
                if (gap < 1000) {
                    lost += gap;
                    consec_drop += gap;
                    if (consec_drop > max_burst_drop) {
                        max_burst_drop = consec_drop;
                    }
                }
            } else {
                consec_drop = 0;
            }
            last_seq = seq;
            total++;
            rssi_sum += rssi;

            int64_t now = k_uptime_ticks();
            if (last_time != 0) {
                int64_t delta_us = k_ticks_to_us_near64(now - last_time);
                int64_t deviation = llabs(delta_us - expected_interval_us);

                if (deviation < iat_min) {
                    iat_min = deviation;
                }
                if (deviation > iat_max) {
                    iat_max = deviation;
                }
                iat_sum += deviation;
                iat_count++;

                if (deviation < 100) {
                    iat_hist[0]++;
                } else if (deviation < 500) {
                    iat_hist[1]++;
                } else if (deviation < 1000) {
                    iat_hist[2]++;
                } else if (deviation < 5000) {
                    iat_hist[3]++;
                } else if (deviation < 10000) {
                    iat_hist[4]++;
                } else {
                    iat_hist[5]++;
                }
            }
            last_time = now;
        }

        /* Print cumulative stats every 5 seconds */
        int64_t now_ms = k_uptime_get();
        if (now_ms - last_print >= 5000) {
            if (total > 0) {
                uint32_t total_pkts = total + lost;
                uint32_t loss_permyriad = (lost * 10000) / total_pkts;
                uint32_t loss_int = loss_permyriad / 100;
                uint32_t loss_frac = loss_permyriad % 100;
                int16_t avg_rssi = (int16_t)(rssi_sum / total);
                int64_t iat_avg = iat_count ? (iat_sum / iat_count) : 0;

                LOG_INF("--- RX Stats (cumulative) ---");
                LOG_INF("  pkts: %u  lost: %u (%u.%02u%%)  burst: %u  RSSI: %d dBm",
                        total, lost, loss_int, loss_frac, max_burst_drop, -avg_rssi);
                LOG_INF("  IAT dev  min: %lld us  avg: %lld us  max: %lld us",
                        iat_min == INT64_MAX ? 0 : iat_min, iat_avg, iat_max);
                LOG_INF("  IAT hist <100us: %u  <500us: %u  <1ms: %u  <5ms: %u  <10ms: %u  >10ms: %u",
                        iat_hist[0], iat_hist[1], iat_hist[2],
                        iat_hist[3], iat_hist[4], iat_hist[5]);
            }
            last_print = now_ms;
        }
    }
}
```

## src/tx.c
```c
#include "radio.h"
#include <zephyr/sys/printk.h>
#include <string.h>

static uint16_t tx_seq;

static void tx_timer_cb(struct k_timer *t)
{
    (void)t;

    if (k_sem_take(&tx_done_sem, K_NO_WAIT) != 0) {
        return;
    }

    nrf_radio_packetptr_set(NRF_RADIO, (uint32_t *)&pkt_tx);

    pkt_tx.seq = tx_seq++;
    memset(pkt_tx.data, 0xAB, sizeof(pkt_tx.data));

    nrf_radio_event_clear(NRF_RADIO, NRF_RADIO_EVENT_DISABLED);
    nrf_radio_task_trigger(NRF_RADIO, NRF_RADIO_TASK_TXEN);
}

static K_TIMER_DEFINE(tx_timer, tx_timer_cb, NULL);

void run_tx(void)
{
    printk("\n=== FlexLink Radio Test TX ===\n");
    printk("Frequency: %u MHz\n", FREQ);
    printk("Rate: 4 Mbps\n");
    printk("TX Power: +8 dBm\n");
    printk("Interval: %u ms\n", INTERVAL_MS);
    printk("Payload: %u bytes\n", PAYLOAD_LEN);
    printk("Sync word: 0x%08lX\n\n", SYNC_WORD);

    nrf_radio_shorts_enable(NRF_RADIO,
        NRF_RADIO_SHORT_READY_START_MASK |
        NRF_RADIO_SHORT_PHYEND_DISABLE_MASK);

    nrf_radio_int_enable(NRF_RADIO,
        NRF_RADIO_INT_DISABLED_MASK);

    irq_enable(RADIO_0_IRQn);

    pkt_tx.seq = 0;
    memset(pkt_tx.data, 0xAB, sizeof(pkt_tx.data));

    k_timer_start(&tx_timer, K_MSEC(INTERVAL_MS), K_MSEC(INTERVAL_MS));

    while (1) {
        k_sleep(K_FOREVER);
    }
}
```
